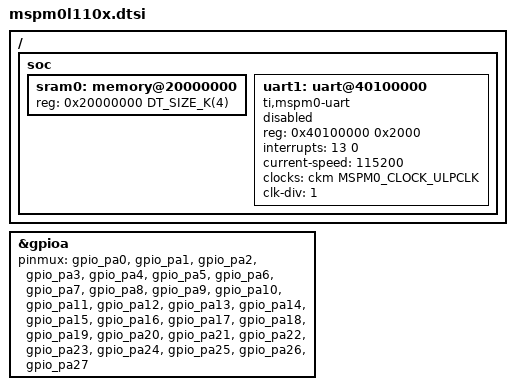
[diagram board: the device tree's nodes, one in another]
/*
 * Copyright (c) 2025 Texas Instruments
 * Copyright (c) 2025 Linumiz GmbH
 *
 * SPDX-License-Identifier: Apache-2.0
 */

#include <mem.h>
#include <ti/mspm0/l/mspm0l.dtsi>

/delete-node/ &gpiob;
/delete-node/ &gpioc;

&gpioa {
	pinmux = <&gpio_pa0>,
		 <&gpio_pa1>,
		 <&gpio_pa2>,
		 <&gpio_pa3>,
		 <&gpio_pa4>,
		 <&gpio_pa5>,
		 <&gpio_pa6>,
		 <&gpio_pa7>,
		 <&gpio_pa8>,
		 <&gpio_pa9>,
		 <&gpio_pa10>,
		 <&gpio_pa11>,
		 <&gpio_pa12>,
		 <&gpio_pa13>,
		 <&gpio_pa14>,
		 <&gpio_pa15>,
		 <&gpio_pa16>,
		 <&gpio_pa17>,
		 <&gpio_pa18>,
		 <&gpio_pa19>,
		 <&gpio_pa20>,
		 <&gpio_pa21>,
		 <&gpio_pa22>,
		 <&gpio_pa23>,
		 <&gpio_pa24>,
		 <&gpio_pa25>,
		 <&gpio_pa26>,
		 <&gpio_pa27>;
};

/ {
	soc {
		sram0: memory@20000000 {
			reg = <0x20000000 DT_SIZE_K(4)>;
		};

		uart1: uart@40100000 {
			compatible = "ti,mspm0-uart";
			reg = <0x40100000 0x2000>;
			interrupts = <13 0>;
			current-speed = <115200>;
			clocks = <&ckm MSPM0_CLOCK_ULPCLK>;
			clk-div = <1>;
			status = "disabled";
		};
	};
};
